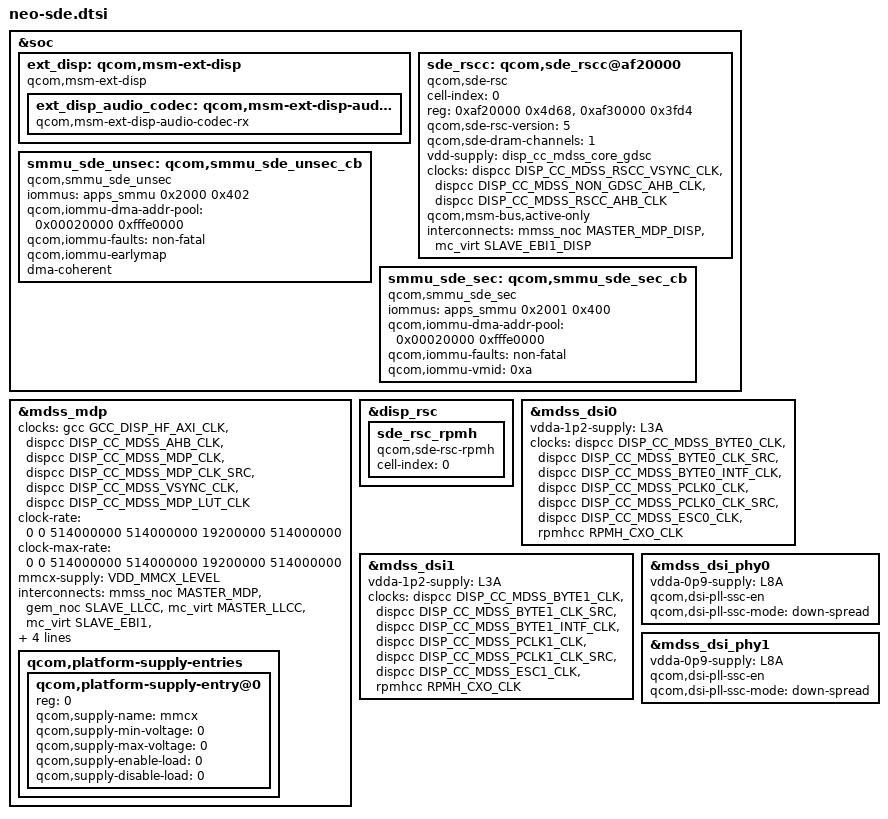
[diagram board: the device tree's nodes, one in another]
#include <dt-bindings/regulator/qcom,rpmh-regulator-levels.h>
#include <dt-bindings/clock/qcom,dispcc-neo.h>
#include <dt-bindings/clock/qcom,gcc-neo.h>
#include <dt-bindings/interconnect/qcom,neo.h>
#include <dt-bindings/clock/qcom,rpmh.h>
#include "neo-sde-common.dtsi"

&soc {
	ext_disp: qcom,msm-ext-disp {
		compatible = "qcom,msm-ext-disp";

		ext_disp_audio_codec: qcom,msm-ext-disp-audio-codec-rx {
			compatible = "qcom,msm-ext-disp-audio-codec-rx";
		};
	};




	sde_rscc: qcom,sde_rscc@af20000 {
		cell-index = <0>;
		compatible = "qcom,sde-rsc";
		reg = <0xaf20000 0x4d68>,
			<0xaf30000 0x3fd4>;
		reg-names = "drv", "wrapper";
		qcom,sde-rsc-version = <5>;

		qcom,sde-dram-channels = <1>;

		vdd-supply = <&disp_cc_mdss_core_gdsc>;
		clocks = <&dispcc DISP_CC_MDSS_RSCC_VSYNC_CLK>,
			<&dispcc DISP_CC_MDSS_NON_GDSC_AHB_CLK>,
			<&dispcc DISP_CC_MDSS_RSCC_AHB_CLK>;
		clock-names = "vsync_clk", "gdsc_clk", "iface_clk";

		qcom,msm-bus,active-only;
		interconnects =
			<&mmss_noc MASTER_MDP_DISP &mc_virt SLAVE_EBI1_DISP>;
		interconnect-names = "qcom,sde-data-bus0";
	};

	smmu_sde_unsec: qcom,smmu_sde_unsec_cb {
		compatible = "qcom,smmu_sde_unsec";
		iommus = <&apps_smmu 0x2000 0x402>;
		qcom,iommu-dma-addr-pool = <0x00020000 0xfffe0000>;
		qcom,iommu-faults = "non-fatal";
		qcom,iommu-earlymap; /* for cont-splash */
		dma-coherent;
	};

	smmu_sde_sec: qcom,smmu_sde_sec_cb {
		compatible = "qcom,smmu_sde_sec";
		iommus = <&apps_smmu 0x2001 0x400>;
		qcom,iommu-dma-addr-pool = <0x00020000 0xfffe0000>;
		qcom,iommu-faults = "non-fatal";
		qcom,iommu-vmid = <0xa>;
	};
};

&mdss_mdp {
	clocks =
		<&gcc GCC_DISP_HF_AXI_CLK>,
		<&dispcc DISP_CC_MDSS_AHB_CLK>,
		<&dispcc DISP_CC_MDSS_MDP_CLK>,
		<&dispcc DISP_CC_MDSS_MDP_CLK_SRC>,
		<&dispcc DISP_CC_MDSS_VSYNC_CLK>,
		<&dispcc DISP_CC_MDSS_MDP_LUT_CLK>;
	clock-names = "gcc_bus",
			"iface_clk", "branch_clk", "core_clk", "vsync_clk",
			"lut_clk";
	clock-rate = <0 0 514000000 514000000 19200000 514000000>;
	clock-max-rate = <0 0 514000000 514000000 19200000 514000000>;

	mmcx-supply = <&VDD_MMCX_LEVEL>;

	/* data and reg bus scale settings */
	interconnects = <&mmss_noc MASTER_MDP &gem_noc SLAVE_LLCC>,
			<&mc_virt MASTER_LLCC &mc_virt SLAVE_EBI1>,
			<&gem_noc MASTER_APPSS_PROC
				&config_noc SLAVE_DISPLAY_CFG>;
	interconnect-names = "qcom,sde-data-bus0",
			"qcom,sde-ebi-bus", "qcom,sde-reg-bus";

	qcom,sde-ib-bw-vote = <2500000 0 1600000>;
	qcom,sde-has-idle-pc;

	qcom,platform-supply-entries {
		#address-cells = <1>;
		#size-cells = <0>;

		qcom,platform-supply-entry@0 {
			reg = <0>;
			qcom,supply-name = "mmcx";
			qcom,supply-min-voltage = <0>;
				qcom,supply-max-voltage = <0>;
				qcom,supply-enable-load = <0>;
				qcom,supply-disable-load = <0>;
			};
	};
};

&disp_rsc {
	sde_rsc_rpmh {
		compatible = "qcom,sde-rsc-rpmh";
		cell-index = <0>;
	};
};

&mdss_dsi0 {
	vdda-1p2-supply = <&L3A>;
	clocks = <&dispcc DISP_CC_MDSS_BYTE0_CLK>,
		<&dispcc DISP_CC_MDSS_BYTE0_CLK_SRC>,
		<&dispcc DISP_CC_MDSS_BYTE0_INTF_CLK>,
		<&dispcc DISP_CC_MDSS_PCLK0_CLK>,
		<&dispcc DISP_CC_MDSS_PCLK0_CLK_SRC>,
		<&dispcc DISP_CC_MDSS_ESC0_CLK>,
		<&rpmhcc RPMH_CXO_CLK>;
	clock-names = "byte_clk", "byte_clk_rcg", "byte_intf_clk",
			"pixel_clk", "pixel_clk_rcg", "esc_clk", "xo";
};

&mdss_dsi1 {
	vdda-1p2-supply = <&L3A>;
	clocks = <&dispcc DISP_CC_MDSS_BYTE1_CLK>,
		<&dispcc DISP_CC_MDSS_BYTE1_CLK_SRC>,
		<&dispcc DISP_CC_MDSS_BYTE1_INTF_CLK>,
		<&dispcc DISP_CC_MDSS_PCLK1_CLK>,
		<&dispcc DISP_CC_MDSS_PCLK1_CLK_SRC>,
		<&dispcc DISP_CC_MDSS_ESC1_CLK>,
		<&rpmhcc RPMH_CXO_CLK>;
	clock-names = "byte_clk", "byte_clk_rcg", "byte_intf_clk",
			"pixel_clk", "pixel_clk_rcg", "esc_clk", "xo";
};

&mdss_dsi_phy0 {
	vdda-0p9-supply = <&L8A>;
	qcom,dsi-pll-ssc-en;
	qcom,dsi-pll-ssc-mode = "down-spread";
};

&mdss_dsi_phy1 {
	vdda-0p9-supply = <&L8A>;
	qcom,dsi-pll-ssc-en;
	qcom,dsi-pll-ssc-mode = "down-spread";
};
